# STM32L562 register map
File version: 1.1
Registers are 32-bit, read-write, reset 0x0 unless marked. A register's access mark holds for its fields unless they carry their own. Offsets are from the block's base; lines under a group give offsets from that group; [hi:lo] are bit positions; {n}, {i} and the like mark numbered series; 'fields as' and 'values as' point back to an identical list; <NAME> marks a mode.

## Memory map
0x40007800 OPAMP size 0x400 — Operational amplifiers

## OPAMP — Operational amplifiers
Base 0x40007800
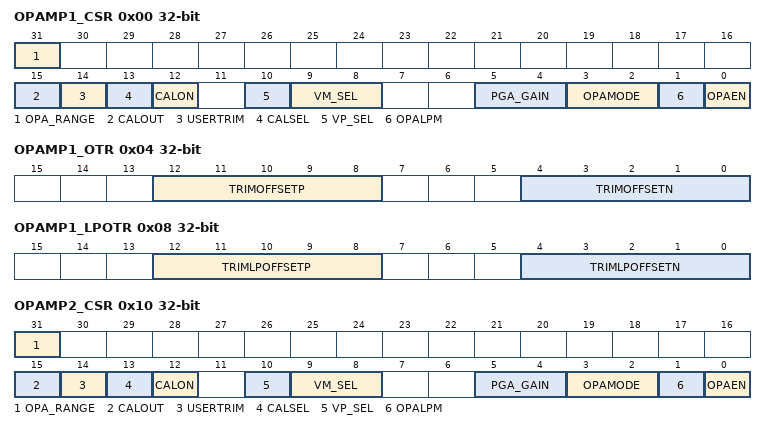
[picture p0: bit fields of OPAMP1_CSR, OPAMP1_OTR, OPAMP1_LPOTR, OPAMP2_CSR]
0x00 OPAMP1_CSR — OPAMP1 control/status register
  [31] OPA_RANGE — Operational amplifier power supply range for stability
  [15] CALOUT — Operational amplifier calibration output
  [14] USERTRIM — User trimming enable
  [13] CALSEL — calibration selection
  [12] CALON — calibration mode enable
  [10] VP_SEL — non inverted input selection
  [9:8] VM_SEL — inverting input selection
  [5:4] PGA_GAIN — Operational amplifier Programmable amplifier gain value
  [3:2] OPAMODE — Operational amplifier PGA mode
  [1] OPALPM — Operational amplifier Low Power Mode
  [0] OPAEN — Operational amplifier Enable
0x04 OPAMP1_OTR — OPAMP1 offset trimming register in normal mode
  [12:8] TRIMOFFSETP — Trim for PMOS differential pairs
  [4:0] TRIMOFFSETN — Trim for NMOS differential pairs
0x08 OPAMP1_LPOTR — OPAMP1 offset trimming register in low-powe mode
  [12:8] TRIMLPOFFSETP — Trim for PMOS differential pairs
  [4:0] TRIMLPOFFSETN — Trim for NMOS differential pairs
0x10 OPAMP2_CSR — OPAMP2 control/status register
  fields as OPAMP1_CSR
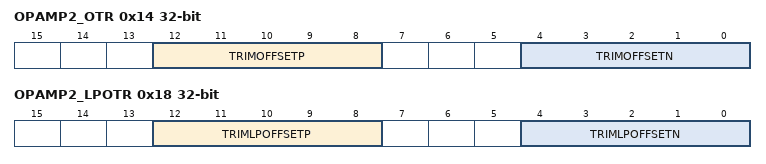
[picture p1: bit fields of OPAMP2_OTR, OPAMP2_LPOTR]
0x14 OPAMP2_OTR — OPAMP2 offset trimming register in normal mode
  fields as OPAMP1_OTR
0x18 OPAMP2_LPOTR — OPAMP2 offset trimming register in low-power mode
  fields as OPAMP1_LPOTR
